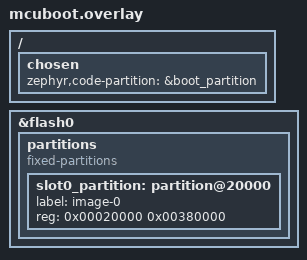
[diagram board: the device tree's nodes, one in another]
/ {
	chosen {
		zephyr,code-partition = &boot_partition;
	};
};

&flash0 {
	partitions {
		compatible = "fixed-partitions";
		#address-cells = <1>;
		#size-cells = <1>;

		/delete-node/ partition@170000;

		slot0_partition: partition@20000 {
			label = "image-0";
			reg = <0x00020000 0x00380000>;
		};
	};
};
